# STM32F103 register map
File version: 1.1
CPU: CM3 r1p1, little endian, no MPU, no FPU, 4 interrupt priority bits
Registers are 32-bit, read-write, reset 0x0 unless marked. A register's access mark holds for its fields unless they carry their own. Offsets are from the block's base; [hi:lo] are bit positions; {n}, {i} and the like mark numbered series.

## SDIO — Secure digital input/output interface
Base 0x40018000
0x00 POWER — Bits 1:0 = PWRCTRL: Power supply control bits
  [1:0] PWRCTRL
    0=PowerOff; 3=PowerOn
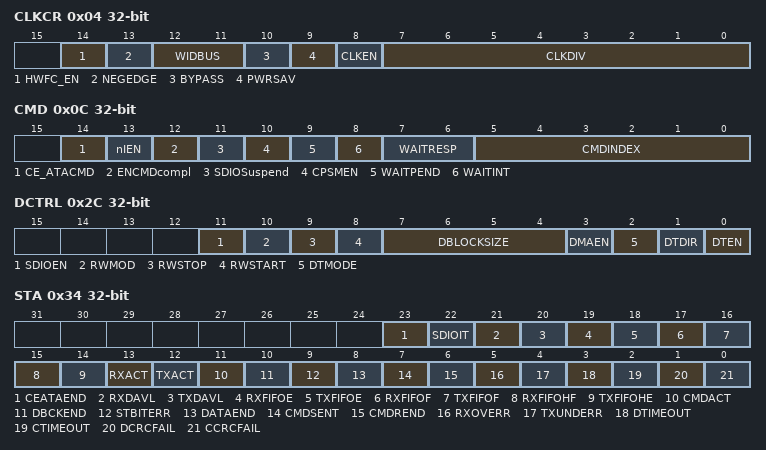
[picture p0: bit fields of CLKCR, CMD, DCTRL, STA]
0x04 CLKCR — SDI clock control register (SDIO_CLKCR)
  [14] HWFC_EN — HW Flow Control enable
    0=Disabled (HW Flow Control is disabled); 1=Enabled (HW Flow Control is enabled)
  [13] NEGEDGE — SDIO_CK dephasing selection bit
    0=Rising (SDIO_CK generated on the rising edge); 1=Falling (SDIO_CK generated on the falling edge)
  [12:11] WIDBUS — Wide bus mode enable bit
    0=BusWidth1 (1 lane wide bus); 1=BusWidth4 (4 lane wide bus); 2=BusWidth8 (8 lane wide bus)
  [10] BYPASS — Clock divider bypass enable bit
    0=Disabled (SDIOCLK is divided according to the CLKDIV value before driving the SDIO_CK output signal.); 1=Enabled (SDIOCLK directly drives the SDIO_CK output signal)
  [9] PWRSAV — Power saving configuration bit
    0=Enabled (SDIO_CK clock is always enabled); 1=Disabled (SDIO_CK is only enabled when the bus is active)
  [8] CLKEN — Clock enable bit
    0=Disabled (Disable clock); 1=Enabled (Enable clock)
  [7:0] CLKDIV — Clock divide factor
0x08 ARG — Bits 31:0 = : Command argument
  [31:0] CMDARG — Command argument
0x0C CMD — SDIO command register (SDIO_CMD)
  [14] CE_ATACMD
    0=Disabled (CE-ATA command disabled); 1=Enabled (CE-ATA command enabled)
  [13] nIEN
    0=Disabled (Interrupts to the CE-ATA not disabled); 1=Enabled (Interrupt to the CE-ATA are disabled)
  [12] ENCMDcompl
    0=Disabled (Command complete signal disabled); 1=Enabled (Command complete signal enabled)
  [11] SDIOSuspend
    0=Disabled (Next command is not a SDIO suspend command); 1=Enabled (Next command send is a SDIO suspend command)
  [10] CPSMEN
    0=Disabled (Command path state machine disabled); 1=Enabled (Command path state machine enabled)
  [9] WAITPEND
    0=Disabled (Don't wait for data end); 1=Enabled (Wait for end of data transfer signal before sending command)
  [8] WAITINT
    0=Disabled (Don't wait for interrupt request); 1=Enabled (Wait for interrupt request)
  [7:6] WAITRESP
    0=NoResponse; 1=ShortResponse; 2=NoResponse2 (No reponse); 3=LongResponse (Long reponse)
  [5:0] CMDINDEX
0x10 RESPCMD ro — SDIO command register
  [5:0] RESPCMD
{0x10+4i} RESP{i} (i=1..4) ro — SDIO response {i} register
  [31:0] CARDSTATUS — Status of a card, which is part of the received response
0x24 DTIMER — Bits 31:0 = DATATIME: Data timeout period
  [31:0] DATATIME — Data timeout period
0x28 DLEN — Bits 24:0 = DATALENGTH: Data length value
  [24:0] DATALENGTH — Data length value
0x2C DCTRL — SDIO data control register (SDIO_DCTRL)
  [11] SDIOEN
    0=Disabled (SDIO operations disabled); 1=Enabled (SDIO operations enabled)
  [10] RWMOD
    0=D2 (Read wait control stopping using SDIO_D2); 1=Ck (Read wait control using SDIO_CK)
  [9] RWSTOP — PWSTOP
    0=Disabled (Read wait in progress if RWSTART is enabled); 1=Enabled (Enable for read wait stop if RWSTART is enabled)
  [8] RWSTART — PWSTART
    0=Disabled (Don't start read wait operation); 1=Enabled (Read wait operation starts)
  [7:4] DBLOCKSIZE
  [3] DMAEN
    0=Disabled (Dma disabled); 1=Enabled (Dma enabled)
  [2] DTMODE
    0=BlockMode (Bloack data transfer); 1=StreamMode (Stream or SDIO multibyte data transfer)
  [1] DTDIR
    0=ControllerToCard (From controller to card); 1=CardToController (From card to controller)
  [0] DTEN
    0=Disabled; 1=Enabled (Start transfer)
0x30 DCOUNT ro — Bits 24:0 = DATACOUNT: Data count value
  [24:0] DATACOUNT — Data count value
0x34 STA ro — SDIO status register (SDIO_STA)
  [23] CEATAEND
    0=NotReceived (Completion signal not received); 1=Received (CE-ATA command completion signal received for CMD61)
  [22] SDIOIT
    0=NotReceived (SDIO interrupt not receieved); 1=Received (SDIO interrupt received)
  [21] RXDAVL
    0=NotAvailable (Data not available in receive FIFO); 1=Available (Data available in receive FIFO)
  [20] TXDAVL
    0=NotAvailable (Data not available in transmit FIFO); 1=Available (Data available in transmit FIFO)
  [19] RXFIFOE
    0=NotEmpty (Receive FIFO not empty); 1=Empty (Receive FIFO empty)
  [18] TXFIFOE
    0=NotEmpty (Transmit FIFO not empty); 1=Empty (Transmit FIFO empty. When HW Flow Control is enabled, TXFIFOE signals becomes activated when the FIFO contains 2 words.)
  [17] RXFIFOF
    0=NotFull (Transmit FIFO not full); 1=Full (Receive FIFO full. When HW Flow Control is enabled, RXFIFOF signals becomes activated 2 words before the FIFO is full.)
  [16] TXFIFOF
    0=NotFull (Transmit FIFO not full); 1=Full (Transmit FIFO full)
  [15] RXFIFOHF
    0=NotHalfFull (Receive FIFO not half full); 1=HalfFull (Receive FIFO half full. At least 8 words in the FIFO)
  [14] TXFIFOHE
    0=NotHalfEmpty (Transmit FIFO not half empty); 1=HalfEmpty (Transmit FIFO half empty. At least 8 words can be written into the FIFO)
  [13] RXACT
    0=NotInProgress (Data receive not in progress); 1=InProgress (Data receive in progress)
  [12] TXACT
    0=NotInProgress (Data transmit is not in progress); 1=InProgress (Data transmit in progress)
  [11] CMDACT
    0=NotInProgress (Command transfer not in progress); 1=InProgress (Command tranfer in progress)
  [10] DBCKEND
    0=NotTransferred (Data block not sent/received (CRC check failed)); 1=Transferred (Data block sent/received (CRC check passed))
  [9] STBITERR
    0=Detected (No start bit detected error); 1=NotDetected (Start bit not detected error)
  [8] DATAEND
    0=NotDone; 1=Done (Data end (DCOUNT, is zero))
  [7] CMDSENT
    0=NotSent (Command not sent); 1=Sent (Command sent (no response required))
  [6] CMDREND
    0=NotDone (Command not done); 1=Done (Command response received (CRC check passed))
  [5] RXOVERR
    0=NoOverrun (No FIFO overrun error); 1=Overrun (Receive FIFO overrun error)
  [4] TXUNDERR
    0=NoUnderrun (No transmit FIFO underrun error); 1=Underrun (Transmit FIFO underrun error)
  [3] DTIMEOUT
    0=NoTimeout (No data timeout); 1=Timeout (Data timeout)
  [2] CTIMEOUT
    0=NoTimeout (No Command timeout); 1=Timeout (Command timeout)
  [1] DCRCFAIL
    0=NotFailed (No Data block sent/received crc check fail); 1=Failed (Data block sent/received crc failed)
  [0] CCRCFAIL
    0=NotFailed (Command response received, crc check passed); 1=Failed (Command response received, crc check failed)
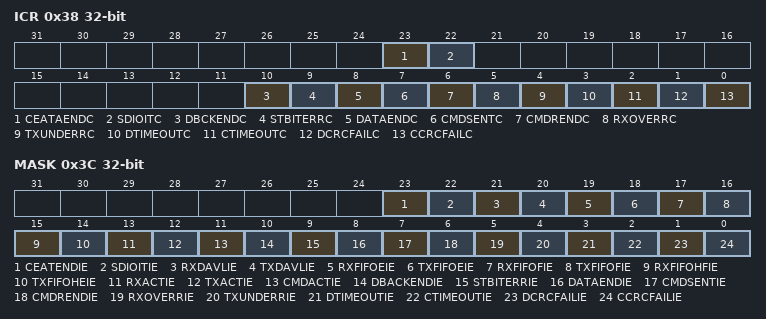
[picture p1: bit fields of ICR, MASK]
0x38 ICR — SDIO interrupt clear register (SDIO_ICR)
  [all] fields
    on write: 1=Clear flag
  [23] CEATAENDC
  [22] SDIOITC
  [10] DBCKENDC
  [9] STBITERRC
  [8] DATAENDC
  [7] CMDSENTC
  [6] CMDRENDC
  [5] RXOVERRC
  [4] TXUNDERRC
  [3] DTIMEOUTC
  [2] CTIMEOUTC
  [1] DCRCFAILC
  [0] CCRCFAILC
0x3C MASK — SDIO mask register (SDIO_MASK)
  [all] fields
    0=Disabled (Interrupt disabled); 1=Enabled (Interrupt enabled)
  [23] CEATENDIE
  [22] SDIOITIE
  [21] RXDAVLIE
  [20] TXDAVLIE
  [19] RXFIFOEIE
  [18] TXFIFOEIE
  [17] RXFIFOFIE
  [16] TXFIFOFIE
  [15] RXFIFOHFIE
  [14] TXFIFOHEIE
  [13] RXACTIE
  [12] TXACTIE
  [11] CMDACTIE
  [10] DBACKENDIE
  [9] STBITERRIE
  [8] DATAENDIE
  [7] CMDSENTIE
  [6] CMDRENDIE
  [5] RXOVERRIE
  [4] TXUNDERRIE
  [3] DTIMEOUTIE
  [2] CTIMEOUTIE
  [1] DCRCFAILIE
  [0] CCRCFAILIE
0x48 FIFOCNT ro — Bits 23:0 = FIFOCOUNT: Remaining number of words to be written to or read from the FIFO
  [23:0] FIFOCOUNT — FIF0COUNT
0x80 FIFO — bits 31:0 = FIFOData: Receive and transmit FIFO data
  [31:0] FIFOData
